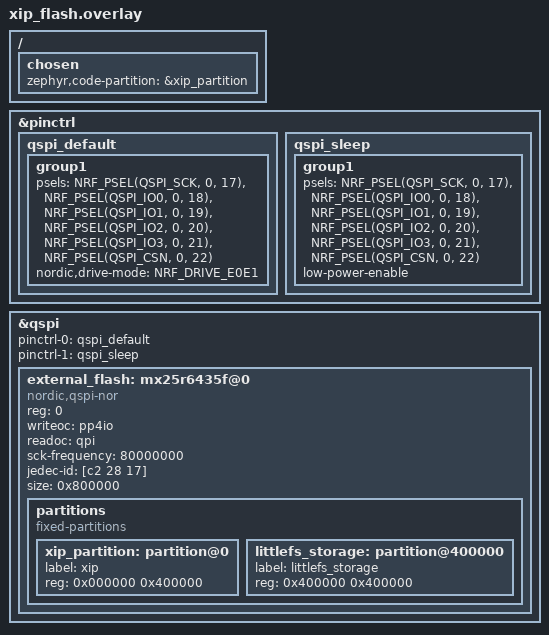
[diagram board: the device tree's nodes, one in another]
/*
 * XIP (eXecute In Place) Configuration for External SPI NOR Flash
 * 8MB MX25R6435F NOR Flash with QSPI interface
 * - 4MB XIP partition for code execution
 * - 4MB LittleFS partition for file system
 */

/ {
    chosen {
        /* Enable XIP execution from external flash */
        zephyr,code-partition = &xip_partition;
    };
};

&pinctrl {
    qspi_default: qspi_default {
        group1 {
            psels = <NRF_PSEL(QSPI_SCK, 0, 17)>,
                    <NRF_PSEL(QSPI_IO0, 0, 18)>,
                    <NRF_PSEL(QSPI_IO1, 0, 19)>,
                    <NRF_PSEL(QSPI_IO2, 0, 20)>,
                    <NRF_PSEL(QSPI_IO3, 0, 21)>,
                    <NRF_PSEL(QSPI_CSN, 0, 22)>;
            nordic,drive-mode = <NRF_DRIVE_E0E1>;
        };
    };

    qspi_sleep: qspi_sleep {
        group1 {
            psels = <NRF_PSEL(QSPI_SCK, 0, 17)>,
                    <NRF_PSEL(QSPI_IO0, 0, 18)>,
                    <NRF_PSEL(QSPI_IO1, 0, 19)>,
                    <NRF_PSEL(QSPI_IO2, 0, 20)>,
                    <NRF_PSEL(QSPI_IO3, 0, 21)>,
                    <NRF_PSEL(QSPI_CSN, 0, 22)>;
            low-power-enable;
        };
    };
};

&qspi {
    status = "okay";
    pinctrl-0 = <&qspi_default>;
    pinctrl-1 = <&qspi_sleep>;
    pinctrl-names = "default", "sleep";

    /* External 8MB NOR Flash - MX25R6435F */
    external_flash: mx25r6435f@0 {
        compatible = "nordic,qspi-nor";
        reg = <0>;
        writeoc = "pp4io";
        readoc = "qpi";
        sck-frequency = <80000000>;
        jedec-id = [c2 28 17];  /* MX25R6435F 8MB NOR Flash */
        size = <0x800000>;      /* 8MB = 0x800000 bytes */
        
        /* Flash partitions */
        partitions {
            compatible = "fixed-partitions";
            #address-cells = <1>;
            #size-cells = <1>;

            /* XIP Partition - First 4MB for code execution */
            xip_partition: partition@0 {
                label = "xip";
                reg = <0x000000 0x400000>;  /* 4MB starting at 0x0 */
            };

            /* LittleFS Partition - Second 4MB for file system */
            littlefs_storage: partition@400000 {
                label = "littlefs_storage";
                reg = <0x400000 0x400000>;  /* 4MB starting at 0x400000 */
            };
        };
    };
};
